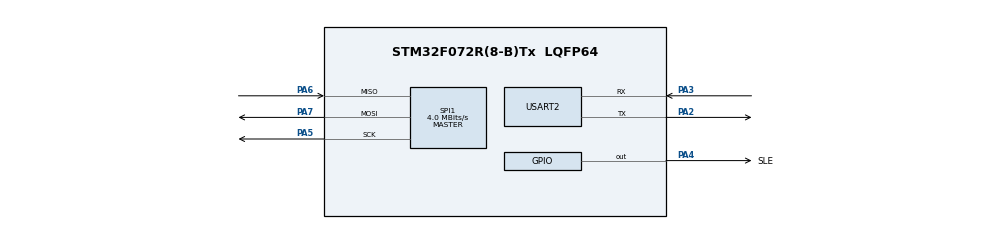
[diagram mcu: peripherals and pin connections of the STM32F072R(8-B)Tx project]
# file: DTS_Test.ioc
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Mcu.Family=STM32F0
Mcu.Name=STM32F072R(8-B)Tx
Mcu.Package=LQFP64
NVIC.SPI1_IRQn=true\:0\:0\:false\:false\:true\:true\:true
NVIC.USART2_IRQn=true\:0\:0\:false\:false\:true\:true\:true
PA2.Mode=Asynchronous
PA2.Signal=USART2_TX
PA3.Mode=Asynchronous
PA3.Signal=USART2_RX
PA4.GPIO_Label=SLE
PA4.Signal=GPIO_Output
PA5.Mode=Full_Duplex_Master
PA5.Signal=SPI1_SCK
PA6.Mode=Full_Duplex_Master
PA6.Signal=SPI1_MISO
PA7.Mode=Full_Duplex_Master
PA7.Signal=SPI1_MOSI
ProjectManager.HeapSize=0x200
ProjectManager.StackSize=0x400
ProjectManager.TargetToolchain=STM32CubeIDE
SPI1.CalculateBaudRate=4.0 MBits/s
SPI1.DataSize=SPI_DATASIZE_8BIT
SPI1.Direction=SPI_DIRECTION_2LINES
SPI1.Mode=SPI_MODE_MASTER
SPI1.VirtualType=VM_MASTER
USART2.VirtualMode-Asynchronous=VM_ASYNC
board=custom

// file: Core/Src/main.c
/* USER CODE BEGIN Header */
/**
  ******************************************************************************
  * @file           : main.c
  * @brief          : Main program body
  ******************************************************************************
  * @attention
  *
  * <h2><center>&copy; Copyright (c) 2020 STMicroelectronics.
  * All rights reserved.</center></h2>
  *
  * This software component is licensed by ST under BSD 3-Clause license,
  * the "License"; You may not use this file except in compliance with the
  * License. You may obtain a copy of the License at:
  *                        opensource.org/licenses/BSD-3-Clause
  *
  ******************************************************************************
  */
/* USER CODE END Header */
#include "main.h"

SPI_HandleTypeDef hspi1;

UART_HandleTypeDef huart2;

/* USER CODE BEGIN PV */
uint8_t receive_spi[12];
int16_t iSensor, iObject;
/* USER CODE END PV */

void SystemClock_Config(void);
static void MX_GPIO_Init(void);
static void MX_SPI1_Init(void);
static void MX_USART2_UART_Init(void);
/* USER CODE BEGIN PFP */
int16_t SPI_COMMAND(uint8_t ADR);
/* USER CODE END PFP */

/* USER CODE BEGIN 0 */
int __io_putchar(int ch) {
	while(HAL_OK != HAL_UART_Transmit(&huart2, (uint8_t*)&ch, 1, 30000)) {

	}

	return ch;
}
/* USER CODE END 0 */

int main(void)
{

  /* MCU Configuration--------------------------------------------------------*/

  /* Reset of all peripherals, Initializes the Flash interface and the Systick. */
  HAL_Init();

  /* Configure the system clock */
  SystemClock_Config();

  /* Initialize all configured peripherals */
  MX_GPIO_Init();
  MX_SPI1_Init();
  MX_USART2_UART_Init();

  /* Infinite loop */
  /* USER CODE BEGIN WHILE */
  while (1)
  {

	  HAL_SPI_Receive_IT(&hspi1, receive_spi, 12);
	  HAL_Delay(1000);

    /* USER CODE END WHILE */

  }
}

void SystemClock_Config(void)
{
  RCC_OscInitTypeDef RCC_OscInitStruct = {0};
  RCC_ClkInitTypeDef RCC_ClkInitStruct = {0};
  RCC_PeriphCLKInitTypeDef PeriphClkInit = {0};

  /** Initializes the RCC Oscillators according to the specified parameters
  * in the RCC_OscInitTypeDef structure.
  */
  RCC_OscInitStruct.OscillatorType = RCC_OSCILLATORTYPE_HSI;
  RCC_OscInitStruct.HSIState = RCC_HSI_ON;
  RCC_OscInitStruct.HSICalibrationValue = RCC_HSICALIBRATION_DEFAULT;
  RCC_OscInitStruct.PLL.PLLState = RCC_PLL_NONE;
  if (HAL_RCC_OscConfig(&RCC_OscInitStruct) != HAL_OK)
  {
    Error_Handler();
  }
  /** Initializes the CPU, AHB and APB buses clocks
  */
  RCC_ClkInitStruct.ClockType = RCC_CLOCKTYPE_HCLK|RCC_CLOCKTYPE_SYSCLK
                              |RCC_CLOCKTYPE_PCLK1;
  RCC_ClkInitStruct.SYSCLKSource = RCC_SYSCLKSOURCE_HSI;
  RCC_ClkInitStruct.AHBCLKDivider = RCC_SYSCLK_DIV1;
  RCC_ClkInitStruct.APB1CLKDivider = RCC_HCLK_DIV1;

  if (HAL_RCC_ClockConfig(&RCC_ClkInitStruct, FLASH_LATENCY_0) != HAL_OK)
  {
    Error_Handler();
  }
  PeriphClkInit.PeriphClockSelection = RCC_PERIPHCLK_USART2;
  PeriphClkInit.Usart2ClockSelection = RCC_USART2CLKSOURCE_PCLK1;
  if (HAL_RCCEx_PeriphCLKConfig(&PeriphClkInit) != HAL_OK)
  {
    Error_Handler();
  }
}

static void MX_SPI1_Init(void)
{

  /* SPI1 parameter configuration*/
  hspi1.Instance = SPI1;
  hspi1.Init.Mode = SPI_MODE_MASTER;
  hspi1.Init.Direction = SPI_DIRECTION_2LINES;
  hspi1.Init.DataSize = SPI_DATASIZE_8BIT;
  hspi1.Init.CLKPolarity = SPI_POLARITY_LOW;
  hspi1.Init.CLKPhase = SPI_PHASE_1EDGE;
  hspi1.Init.NSS = SPI_NSS_SOFT;
  hspi1.Init.BaudRatePrescaler = SPI_BAUDRATEPRESCALER_2;
  hspi1.Init.FirstBit = SPI_FIRSTBIT_MSB;
  hspi1.Init.TIMode = SPI_TIMODE_DISABLE;
  hspi1.Init.CRCCalculation = SPI_CRCCALCULATION_DISABLE;
  hspi1.Init.CRCPolynomial = 7;
  hspi1.Init.CRCLength = SPI_CRC_LENGTH_DATASIZE;
  hspi1.Init.NSSPMode = SPI_NSS_PULSE_ENABLE;
  if (HAL_SPI_Init(&hspi1) != HAL_OK)
  {
    Error_Handler();
  }

}

static void MX_USART2_UART_Init(void)
{

  huart2.Instance = USART2;
  huart2.Init.BaudRate = 38400;
  huart2.Init.WordLength = UART_WORDLENGTH_8B;
  huart2.Init.StopBits = UART_STOPBITS_1;
  huart2.Init.Parity = UART_PARITY_NONE;
  huart2.Init.Mode = UART_MODE_TX_RX;
  huart2.Init.HwFlowCtl = UART_HWCONTROL_NONE;
  huart2.Init.OverSampling = UART_OVERSAMPLING_16;
  huart2.Init.OneBitSampling = UART_ONE_BIT_SAMPLE_DISABLE;
  huart2.AdvancedInit.AdvFeatureInit = UART_ADVFEATURE_NO_INIT;
  if (HAL_UART_Init(&huart2) != HAL_OK)
  {
    Error_Handler();
  }

}

static void MX_GPIO_Init(void)
{
  GPIO_InitTypeDef GPIO_InitStruct = {0};

  /* GPIO Ports Clock Enable */
  __HAL_RCC_GPIOA_CLK_ENABLE();

  /*Configure GPIO pin Output Level */
  HAL_GPIO_WritePin(SLE_GPIO_Port, SLE_Pin, GPIO_PIN_RESET);

  /*Configure GPIO pin : SLE_Pin */
  GPIO_InitStruct.Pin = SLE_Pin;
  GPIO_InitStruct.Mode = GPIO_MODE_OUTPUT_PP;
  GPIO_InitStruct.Pull = GPIO_NOPULL;
  GPIO_InitStruct.Speed = GPIO_SPEED_FREQ_LOW;
  HAL_GPIO_Init(SLE_GPIO_Port, &GPIO_InitStruct);

}

/* USER CODE BEGIN 4 */
void HAL_SPI_RxCpltCallback(SPI_HandleTypeDef *hspi) {
	printf("CallBack_Start\r\n");
	if(hspi->Instance == SPI1) {
		for(int i=0; i<12; i++) {
			printf("%x\r\n", receive_spi[i]);
		}
		printf("%x\r\n", receive_spi);
	}
}
/* USER CODE END 4 */

void Error_Handler(void)
{
  __disable_irq();
  while (1)
  {
  }
}

/************************ (C) COPYRIGHT STMicroelectronics *****END OF FILE****/
